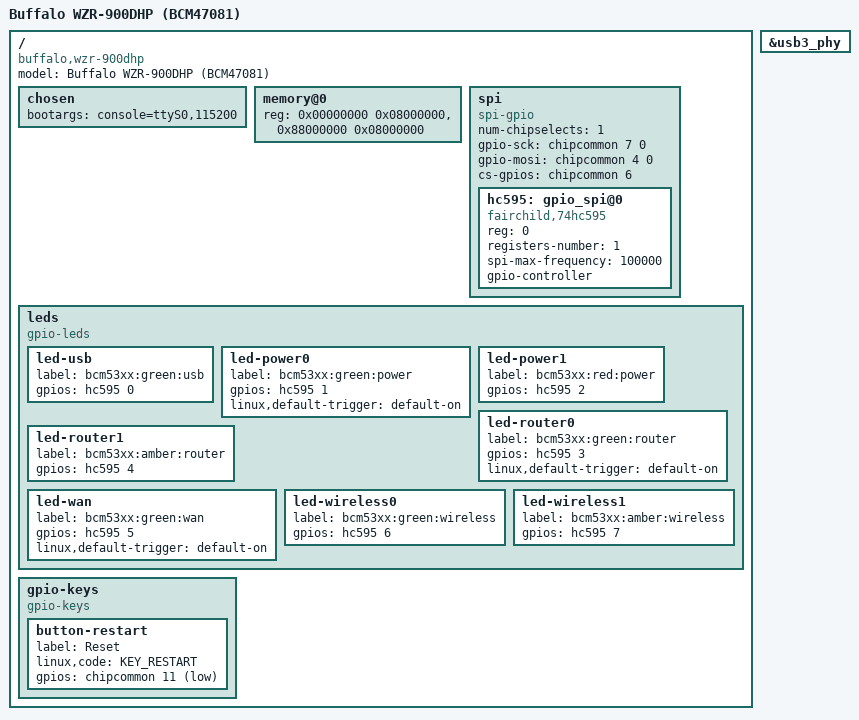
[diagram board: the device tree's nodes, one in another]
// SPDX-License-Identifier: GPL-2.0-or-later OR MIT
/*
 * Broadcom BCM470X / BCM5301X ARM platform code.
 * DTS for Buffalo WZR-900DHP
 *
 * Copyright (C) 2015 Rafał Miłecki <zajec5@gmail.com>
 */

/dts-v1/;

#include "bcm47081.dtsi"
#include "bcm5301x-nand-cs0-bch8.dtsi"

/ {
	compatible = "buffalo,wzr-900dhp", "brcm,bcm47081", "brcm,bcm4708";
	model = "Buffalo WZR-900DHP (BCM47081)";

	chosen {
		bootargs = "console=ttyS0,115200";
	};

	memory@0 {
		device_type = "memory";
		reg = <0x00000000 0x08000000>,
		      <0x88000000 0x08000000>;
	};

	spi {
		compatible = "spi-gpio";
		num-chipselects = <1>;
		gpio-sck = <&chipcommon 7 0>;
		gpio-mosi = <&chipcommon 4 0>;
		cs-gpios = <&chipcommon 6 0>;
		#address-cells = <1>;
		#size-cells = <0>;

		hc595: gpio_spi@0 {
			compatible = "fairchild,74hc595";
			reg = <0>;
			registers-number = <1>;
			spi-max-frequency = <100000>;

			gpio-controller;
			#gpio-cells = <2>;

		};
	};

	leds {
		compatible = "gpio-leds";

		led-usb {
			label = "bcm53xx:green:usb";
			gpios = <&hc595 0 GPIO_ACTIVE_HIGH>;
		};

		led-power0 {
			label = "bcm53xx:green:power";
			gpios = <&hc595 1 GPIO_ACTIVE_HIGH>;
			linux,default-trigger = "default-on";
		};

		led-power1 {
			label = "bcm53xx:red:power";
			gpios = <&hc595 2 GPIO_ACTIVE_HIGH>;
		};

		led-router0 {
			label = "bcm53xx:green:router";
			gpios = <&hc595 3 GPIO_ACTIVE_HIGH>;
			linux,default-trigger = "default-on";
		};

		led-router1 {
			label = "bcm53xx:amber:router";
			gpios = <&hc595 4 GPIO_ACTIVE_HIGH>;
		};

		led-wan {
			label = "bcm53xx:green:wan";
			gpios = <&hc595 5 GPIO_ACTIVE_HIGH>;
			linux,default-trigger = "default-on";
		};

		led-wireless0 {
			label = "bcm53xx:green:wireless";
			gpios = <&hc595 6 GPIO_ACTIVE_HIGH>;
		};

		led-wireless1 {
			label = "bcm53xx:amber:wireless";
			gpios = <&hc595 7 GPIO_ACTIVE_HIGH>;
		};
	};

	gpio-keys {
		compatible = "gpio-keys";

		button-restart {
			label = "Reset";
			linux,code = <KEY_RESTART>;
			gpios = <&chipcommon 11 GPIO_ACTIVE_LOW>;
		};
	};
};

&usb3_phy {
	status = "okay";
};
